AUTOSAR XML (schema 00044)
package /E40_Platform_System_SystemPackage/Components
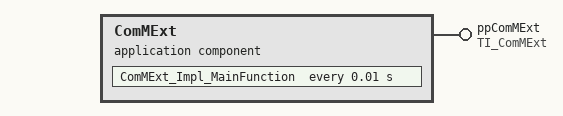
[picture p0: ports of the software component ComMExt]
  application sw component type ComMExt
    provide port ppComMExt: provided-interface=TI_ComMExt
      provided-com-specs:
        operation=CAN_ActivateSilentCommunication, queue-length=1
        operation=CAN_CommControlActivateRx, queue-length=1
        operation=CAN_CommControlActivateTx, queue-length=1
        operation=CAN_CommControlDeActivateRx, queue-length=1
        operation=CAN_CommControlDeActivateTx, queue-length=1
        operation=CAN_CommControlSetDone, queue-length=1
        operation=CAN_DeActivateSilentCommunication, queue-length=1
        operation=CAN_GetCurrentComMode, queue-length=1
        operation=CAN_ReleaseCommunication, queue-length=1
        operation=CAN_RequestCommunication, queue-length=1
        operation=GetBusOffStatus, queue-length=1
        operation=Get_MCAN_ERR_PIN_Status, queue-length=1
        operation=Init, queue-length=1
    behavior IB_ComMExt: port-api-option{enable-take-address=false, indirect-api=false, port=ppComMExt}
      12 x operation invoked event:
        OIE_ppComMExt_ComMExt_CAN_ActivateSilentCommunicationTrigByCAN_ActivateSilentCommunication: start-on-event=ComMExt_CAN_ActivateSilentCommunication, operation=ppComMExt.CAN_ActivateSilentCommunication
        OIE_ppComMExt_ComMExt_CAN_CommControlActivateRxTrigByCAN_CommControlActivateRx: start-on-event=ComMExt_CAN_CommControlActivateRx, operation=ppComMExt.CAN_CommControlActivateRx
        OIE_ppComMExt_ComMExt_CAN_CommControlActivateTxTrigByCAN_CommControlActivateTx: start-on-event=ComMExt_CAN_CommControlActivateTx, operation=ppComMExt.CAN_CommControlActivateTx
        OIE_ppComMExt_ComMExt_CAN_CommControlDeActivateRxTrigByCAN_CommControlDeActivateRx: start-on-event=ComMExt_CAN_CommControlDeActivateRx, operation=ppComMExt.CAN_CommControlDeActivateRx
        OIE_ppComMExt_ComMExt_CAN_CommControlDeActivateTxTrigByCAN_CommControlDeActivateTx: start-on-event=ComMExt_CAN_CommControlDeActivateTx, operation=ppComMExt.CAN_CommControlDeActivateTx
        OIE_ppComMExt_ComMExt_CAN_CommControlSetDoneTrigByCAN_CommControlSetDone: start-on-event=ComMExt_CAN_CommControlSetDone, operation=ppComMExt.CAN_CommControlSetDone
        OIE_ppComMExt_ComMExt_CAN_DeActivateSilentCommunicationTrigByCAN_DeActivateSilentCommunication: start-on-event=ComMExt_CAN_DeActivateSilentCommunication, operation=ppComMExt.CAN_DeActivateSilentCommunication
        OIE_ppComMExt_ComMExt_CAN_GetCurrentComModeTrigByCAN_GetCurrentComMode: start-on-event=ComMExt_CAN_GetCurrentComMode, operation=ppComMExt.CAN_GetCurrentComMode
        OIE_ppComMExt_ComMExt_CAN_ReleaseCommunicationTrigByCAN_ReleaseCommunication: start-on-event=ComMExt_CAN_ReleaseCommunication, operation=ppComMExt.CAN_ReleaseCommunication
        OIE_ppComMExt_ComMExt_CAN_RequestCommunicationTrigByCAN_RequestCommunication: start-on-event=ComMExt_CAN_RequestCommunication, operation=ppComMExt.CAN_RequestCommunication
        OIE_ppComMExt_ComMExt_GetBusOffStatusTrigByGetBusOffStatus: start-on-event=ComMExt_GetBusOffStatus, operation=ppComMExt.GetBusOffStatus
        OIE_ppComMExt_ComMExt_Get_MCAN_ERR_PIN_StatusTrigByGet_MCAN_ERR_PIN_Status: start-on-event=ComMExt_Get_MCAN_ERR_PIN_Status, operation=ppComMExt.Get_MCAN_ERR_PIN_Status
      timing event TEComMExt_Impl_MainFunction: start-on-event=ComMExt_Impl_MainFunction, period=0.01
      operation invoked event OIE_ppComMExt_ComMExt_InitTrigByInit: start-on-event=ComMExt_Init, operation=ppComMExt.Init
      14 x runnable, all with can-be-invoked-concurrently=true:
        ComMExt_Init
        ComMExt_Impl_MainFunction
        ComMExt_Get_MCAN_ERR_PIN_Status
        ComMExt_GetBusOffStatus
        ComMExt_CAN_RequestCommunication
        ComMExt_CAN_ReleaseCommunication
        ComMExt_CAN_GetCurrentComMode
        ComMExt_CAN_DeActivateSilentCommunication
        ComMExt_CAN_CommControlSetDone
        ComMExt_CAN_CommControlDeActivateTx
        ComMExt_CAN_CommControlDeActivateRx
        ComMExt_CAN_CommControlActivateTx
        ComMExt_CAN_CommControlActivateRx
        ComMExt_CAN_ActivateSilentCommunication
  swc implementation IMPL_ComMExt: behavior=IB_ComMExt
